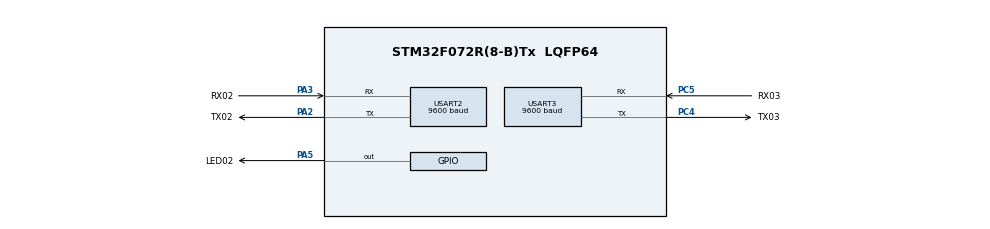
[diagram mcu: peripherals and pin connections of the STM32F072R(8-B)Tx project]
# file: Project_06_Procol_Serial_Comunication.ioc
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Mcu.Family=STM32F0
Mcu.Name=STM32F072R(8-B)Tx
Mcu.Package=LQFP64
NVIC.USART2_IRQn=true\:0\:0\:false\:false\:true\:true\:true\:true
NVIC.USART3_4_IRQn=true\:0\:0\:false\:false\:true\:true\:true\:true
PA2.GPIO_Label=TX02
PA2.Mode=Asynchronous
PA2.Signal=USART2_TX
PA3.GPIO_Label=RX02
PA3.Mode=Asynchronous
PA3.Signal=USART2_RX
PA5.GPIO_Label=LED02
PA5.Signal=GPIO_Output
PC4.GPIO_Label=TX03
PC4.Mode=Asynchronous
PC4.Signal=USART3_TX
PC5.GPIO_Label=RX03
PC5.Mode=Asynchronous
PC5.Signal=USART3_RX
ProjectManager.HeapSize=0x200
ProjectManager.StackSize=0x400
ProjectManager.TargetToolchain=STM32CubeIDE
USART2.BaudRate=9600
USART2.VirtualMode-Asynchronous=VM_ASYNC
USART3.BaudRate=9600
USART3.VirtualMode-Asynchronous=VM_ASYNC
board=custom

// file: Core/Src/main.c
/* USER CODE BEGIN Header */
/**
  ******************************************************************************
  * @file           : main.c
  * @brief          : Main program body
  ******************************************************************************
  * @attention
  *
  * Copyright (c) 2022 STMicroelectronics.
  * All rights reserved.
  *
  * This software is licensed under terms that can be found in the LICENSE file
  * in the root directory of this software component.
  * If no LICENSE file comes with this software, it is provided AS-IS.
  *
  ******************************************************************************
  */
/* USER CODE END Header */
#include "main.h"

/* USER CODE BEGIN Includes */
#include <stdio.h>
#include <string.h>

/* USER CODE END Includes */

UART_HandleTypeDef huart2;
UART_HandleTypeDef huart3;

#define comand_high  HAL_GPIO_WritePin(GPIOA,GPIO_PIN_5,GPIO_PIN_SET);
#define comand_low HAL_GPIO_WritePin(GPIOA,GPIO_PIN_5,GPIO_PIN_RESET);
#define delay_00 HAL_Delay(750);
#define delay_01 HAL_Delay(450);

void pisca_led (x,y,z,t){ //pesquisar sobre funções, e qual é a diferença da uma fuunção void para uma int, char....

	for (int i = 0; i <= z; i++){

		HAL_GPIO_WritePin(x,y,GPIO_PIN_SET);
		HAL_Delay(t);
		HAL_GPIO_WritePin(x,y,GPIO_PIN_RESET);
		HAL_Delay(t);

	}

}

void SystemClock_Config(void);
static void MX_GPIO_Init(void);
static void MX_USART2_UART_Init(void);
static void MX_USART3_UART_Init(void);

int main(void)
{
  /* USER CODE BEGIN 1 */
  uint8_t rx_buffer[5] = {0};
  uint8_t rec_bit[] = "\r\n\n informacao recebida com sucesso!\r\n\n";
  uint8_t erro_bit[] = "\r\n\n Informacao incorreta!\r\n\n";

  memset(rx_buffer,0,sizeof(rx_buffer));

  /* USER CODE END 1 */

  /* MCU Configuration--------------------------------------------------------*/

  /* Reset of all peripherals, Initializes the Flash interface and the Systick. */
  HAL_Init();

  /* Configure the system clock */
  SystemClock_Config();

  /* Initialize all configured peripherals */
  MX_GPIO_Init();
  MX_USART2_UART_Init();
  MX_USART3_UART_Init();

  /* Infinite loop */
  /* USER CODE BEGIN WHILE */

  while (1)
  {

	  HAL_StatusTypeDef statusRX;
	  statusRX = HAL_UART_Receive_IT(&huart3,rx_buffer,5);

	  if (statusRX == HAL_OK)
	  {
		  if((rx_buffer[0] == 'L') && (rx_buffer[1] == 'U') && (rx_buffer[2] == 'P') && (rx_buffer[3] == 'A') )
		  {

			  HAL_UART_Transmit(&huart3,rec_bit,sizeof(rec_bit),100);

			  if (rx_buffer[4] == 'H'){

				pisca_led(GPIOA,GPIO_PIN_5,1,1000);

			  }

			  if (rx_buffer[4] == 'P')
			  {

				  pisca_led(GPIOA,GPIO_PIN_5,3,500);

			  }

			  HAL_UART_Transmit(&huart3,rx_buffer,sizeof(rx_buffer),100);

			  rx_buffer[0] = 0;
			  rx_buffer[1] = 0;
			  rx_buffer[3] = 0;
			  rx_buffer[4] = 0;
			  rx_buffer[5] = 0;

		  }

	  }
	  else
	  {

	  }

}

}
void SystemClock_Config(void)
{
  RCC_OscInitTypeDef RCC_OscInitStruct = {0};
  RCC_ClkInitTypeDef RCC_ClkInitStruct = {0};
  RCC_PeriphCLKInitTypeDef PeriphClkInit = {0};

  /** Initializes the RCC Oscillators according to the specified parameters
  * in the RCC_OscInitTypeDef structure.
  */
  RCC_OscInitStruct.OscillatorType = RCC_OSCILLATORTYPE_HSI;
  RCC_OscInitStruct.HSIState = RCC_HSI_ON;
  RCC_OscInitStruct.HSICalibrationValue = RCC_HSICALIBRATION_DEFAULT;
  RCC_OscInitStruct.PLL.PLLState = RCC_PLL_NONE;
  if (HAL_RCC_OscConfig(&RCC_OscInitStruct) != HAL_OK)
  {
    Error_Handler();
  }

  /** Initializes the CPU, AHB and APB buses clocks
  */
  RCC_ClkInitStruct.ClockType = RCC_CLOCKTYPE_HCLK|RCC_CLOCKTYPE_SYSCLK
                              |RCC_CLOCKTYPE_PCLK1;
  RCC_ClkInitStruct.SYSCLKSource = RCC_SYSCLKSOURCE_HSI;
  RCC_ClkInitStruct.AHBCLKDivider = RCC_SYSCLK_DIV1;
  RCC_ClkInitStruct.APB1CLKDivider = RCC_HCLK_DIV1;

  if (HAL_RCC_ClockConfig(&RCC_ClkInitStruct, FLASH_LATENCY_0) != HAL_OK)
  {
    Error_Handler();
  }
  PeriphClkInit.PeriphClockSelection = RCC_PERIPHCLK_USART2;
  PeriphClkInit.Usart2ClockSelection = RCC_USART2CLKSOURCE_PCLK1;
  if (HAL_RCCEx_PeriphCLKConfig(&PeriphClkInit) != HAL_OK)
  {
    Error_Handler();
  }
}

static void MX_USART2_UART_Init(void)
{

  huart2.Instance = USART2;
  huart2.Init.BaudRate = 9600;
  huart2.Init.WordLength = UART_WORDLENGTH_8B;
  huart2.Init.StopBits = UART_STOPBITS_1;
  huart2.Init.Parity = UART_PARITY_NONE;
  huart2.Init.Mode = UART_MODE_TX_RX;
  huart2.Init.HwFlowCtl = UART_HWCONTROL_NONE;
  huart2.Init.OverSampling = UART_OVERSAMPLING_16;
  huart2.Init.OneBitSampling = UART_ONE_BIT_SAMPLE_DISABLE;
  huart2.AdvancedInit.AdvFeatureInit = UART_ADVFEATURE_NO_INIT;
  if (HAL_UART_Init(&huart2) != HAL_OK)
  {
    Error_Handler();
  }

}

static void MX_USART3_UART_Init(void)
{

  huart3.Instance = USART3;
  huart3.Init.BaudRate = 9600;
  huart3.Init.WordLength = UART_WORDLENGTH_8B;
  huart3.Init.StopBits = UART_STOPBITS_1;
  huart3.Init.Parity = UART_PARITY_NONE;
  huart3.Init.Mode = UART_MODE_TX_RX;
  huart3.Init.HwFlowCtl = UART_HWCONTROL_NONE;
  huart3.Init.OverSampling = UART_OVERSAMPLING_16;
  huart3.Init.OneBitSampling = UART_ONE_BIT_SAMPLE_DISABLE;
  huart3.AdvancedInit.AdvFeatureInit = UART_ADVFEATURE_NO_INIT;
  if (HAL_UART_Init(&huart3) != HAL_OK)
  {
    Error_Handler();
  }

}

static void MX_GPIO_Init(void)
{
  GPIO_InitTypeDef GPIO_InitStruct = {0};

  /* GPIO Ports Clock Enable */
  __HAL_RCC_GPIOA_CLK_ENABLE();
  __HAL_RCC_GPIOC_CLK_ENABLE();

  /*Configure GPIO pin Output Level */
  HAL_GPIO_WritePin(LED02_GPIO_Port, LED02_Pin, GPIO_PIN_RESET);

  /*Configure GPIO pin : LED02_Pin */
  GPIO_InitStruct.Pin = LED02_Pin;
  GPIO_InitStruct.Mode = GPIO_MODE_OUTPUT_PP;
  GPIO_InitStruct.Pull = GPIO_NOPULL;
  GPIO_InitStruct.Speed = GPIO_SPEED_FREQ_LOW;
  HAL_GPIO_Init(LED02_GPIO_Port, &GPIO_InitStruct);

}

void Error_Handler(void)
{
  __disable_irq();
  while (1)
  {
  }
}
